AUTOSAR XML (schema 00044)
package /COMPOSITION_SWC_LAB
  sender receiver interface SR_LightControl
    data LightControl: type=uint16
  sender receiver interface SR_LightActuate
    data LightActuate: type=uint16
  sensor actuator sw component type SWC_LightControl_Status
    provide port PP_SR_LightControl_Status: provided-interface=SR_LightControl
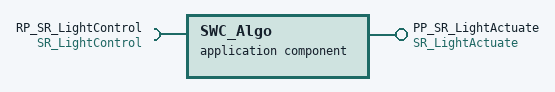
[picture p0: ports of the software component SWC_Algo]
  application sw component type SWC_Algo
    provide port PP_SR_LightActuate: provided-interface=SR_LightActuate
    require port RP_SR_LightControl: required-interface=SR_LightControl
  sensor actuator sw component type SWC_LightActuate
    require port RP_SR_LightActuate: required-interface=SR_LightActuate
  composition sw component type SWC_Composite1
    provide port PP_SR_COMP_LightActuate: provided-interface=SR_LightActuate
    component COMP1_SWC1: type=SWC_LightControl_Status
    component COMP1_SWC2: type=SWC_Algo
    connect COMP1_SWC1.PP_SR_LightControl_Status -> COMP1_SWC2.RP_SR_LightControl
    delegate COMP1_SWC2.PP_SR_LightActuate <-> outer port RP_SR_LightControl_Status
  composition sw component type SWC_Composite2
    component COMP2_SWC1: type=SWC_Composite1
    component COMP2_SWC3: type=SWC_LightActuate
    connect SWC_Composite1.PP_SR_COMP_LightActuate -> SWC_LightActuate.RP_SR_LightActuate
